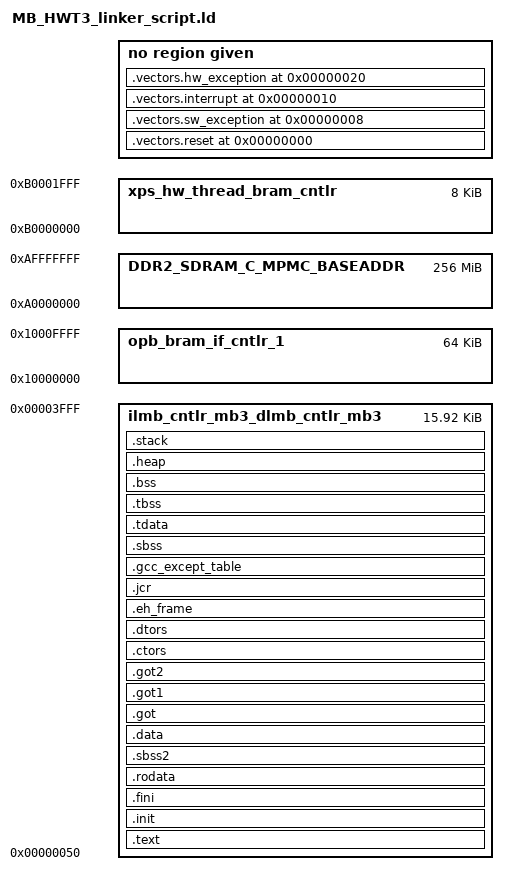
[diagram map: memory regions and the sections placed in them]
/*******************************************************************/
/*                                                                 */
/* This file is automatically generated by linker script generator.*/
/*                                                                 */
/* Version: Xilinx EDK 10.1.03 EDK_K_SP3.6                                */
/*                                                                 */
/* Copyright (c) 2004 Xilinx, Inc.  All rights reserved.           */
/*                                                                 */
/* Description : MicroBlaze Linker Script                          */
/*                                                                 */
/*******************************************************************/

_STACK_SIZE = DEFINED(_STACK_SIZE) ? _STACK_SIZE : 0x400;
_HEAP_SIZE = DEFINED(_HEAP_SIZE) ? _HEAP_SIZE : 0x0;

/* Define Memories in the system */

MEMORY
{
   ilmb_cntlr_mb3_dlmb_cntlr_mb3 : ORIGIN = 0x00000050, LENGTH = 0x00003FB0
   opb_bram_if_cntlr_1 : ORIGIN = 0x10000000, LENGTH = 0x00010000
   DDR2_SDRAM_C_MPMC_BASEADDR : ORIGIN = 0xA0000000, LENGTH = 0x10000000
   xps_hw_thread_bram_cntlr : ORIGIN = 0xB0000000, LENGTH = 0x00002000
}

/* Specify the default entry point to the program */

ENTRY(_start)

/* Define the sections, and where they are mapped in memory */

SECTIONS
{
.vectors.reset 0x00000000 : {
   *(.vectors.reset)
} 

.vectors.sw_exception 0x00000008 : {
   *(.vectors.sw_exception)
} 

.vectors.interrupt 0x00000010 : {
   *(.vectors.interrupt)
} 

.vectors.hw_exception 0x00000020 : {
   *(.vectors.hw_exception)
} 

.text : {
   *(.text)
   *(.text.*)
   *(.gnu.linkonce.t.*)
} > ilmb_cntlr_mb3_dlmb_cntlr_mb3

.init : {
   KEEP (*(.init))
} > ilmb_cntlr_mb3_dlmb_cntlr_mb3

.fini : {
   KEEP (*(.fini))
} > ilmb_cntlr_mb3_dlmb_cntlr_mb3

.rodata : {
   __rodata_start = .;
   *(.rodata)
   *(.rodata.*)
   *(.gnu.linkonce.r.*)
   __rodata_end = .;
} > ilmb_cntlr_mb3_dlmb_cntlr_mb3

.sbss2 : {
   __sbss2_start = .;
   *(.sbss2)
   *(.sbss2.*)
   *(.gnu.linkonce.sb2.*)
   __sbss2_end = .;
} > ilmb_cntlr_mb3_dlmb_cntlr_mb3

.data : {
   . = ALIGN(4);
   __data_start = .;
   *(.data)
   *(.data.*)
   *(.gnu.linkonce.d.*)
   __data_end = .;
} > ilmb_cntlr_mb3_dlmb_cntlr_mb3

.got : {
   *(.got)
} > ilmb_cntlr_mb3_dlmb_cntlr_mb3

.got1 : {
   *(.got1)
} > ilmb_cntlr_mb3_dlmb_cntlr_mb3

.got2 : {
   *(.got2)
} > ilmb_cntlr_mb3_dlmb_cntlr_mb3

.ctors : {
   __CTOR_LIST__ = .;
   ___CTORS_LIST___ = .;
   KEEP (*crtbegin.o(.ctors))
   KEEP (*(EXCLUDE_FILE(*crtend.o) .ctors))
   KEEP (*(SORT(.ctors.*)))
   KEEP (*(.ctors))
   __CTOR_END__ = .;
   ___CTORS_END___ = .;
} > ilmb_cntlr_mb3_dlmb_cntlr_mb3

.dtors : {
   __DTOR_LIST__ = .;
   ___DTORS_LIST___ = .;
   KEEP (*crtbegin.o(.dtors))
   KEEP (*(EXCLUDE_FILE(*crtend.o) .dtors))
   KEEP (*(SORT(.dtors.*)))
   KEEP (*(.dtors))
   __DTOR_END__ = .;
   ___DTORS_END___ = .;
} > ilmb_cntlr_mb3_dlmb_cntlr_mb3

.eh_frame : {
   *(.eh_frame)
} > ilmb_cntlr_mb3_dlmb_cntlr_mb3

.jcr : {
   *(.jcr)
} > ilmb_cntlr_mb3_dlmb_cntlr_mb3

.gcc_except_table : {
   *(.gcc_except_table)
} > ilmb_cntlr_mb3_dlmb_cntlr_mb3

.sbss : {
   . = ALIGN(4);
   __sbss_start = .;
   *(.sbss)
   *(.sbss.*)
   *(.gnu.linkonce.sb.*)
   . = ALIGN(8);
   __sbss_end = .;
} > ilmb_cntlr_mb3_dlmb_cntlr_mb3

.tdata : {
   __tdata_start = .;
   *(.tdata)
   *(.tdata.*)
   *(.gnu.linkonce.td.*)
   __tdata_end = .;
} > ilmb_cntlr_mb3_dlmb_cntlr_mb3

.tbss : {
   __tbss_start = .;
   *(.tbss)
   *(.tbss.*)
   *(.gnu.linkonce.tb.*)
   __tbss_end = .;
} > ilmb_cntlr_mb3_dlmb_cntlr_mb3

.bss : {
   . = ALIGN(4);
   __bss_start = .;
   *(.bss)
   *(.bss.*)
   *(.gnu.linkonce.b.*)
   *(COMMON)
   . = ALIGN(4);
   __bss_end = .;
} > ilmb_cntlr_mb3_dlmb_cntlr_mb3

_SDA_BASE_ = ((__sbss_end - __sbss_start) / 2 );

_SDA2_BASE_ = ((__sbss2_end - __sbss2_start) / 2 );

/* Generate Stack and Heap definitions */

.heap : {
   . = ALIGN(8);
   _heap = .;
   _heap_start = .;
   . += _HEAP_SIZE;
   _heap_end = .;
} > ilmb_cntlr_mb3_dlmb_cntlr_mb3

.stack : {
   _stack_end = .;
   . += _STACK_SIZE;
   . = ALIGN(8);
   _stack = .;
   __stack = _stack;
} > ilmb_cntlr_mb3_dlmb_cntlr_mb3

}

